# CALC3_BFSW_ICONT register map
Vendor: Texas Instruments
Peripheral module from a debugger description file (folder DRA74xP_75xP_76xP_77xP).
Registers are 32-bit, access per field, reset 0x0 unless marked. A register's access mark holds for its fields unless they carry their own. Offsets are as the file gives them; lines under a group give offsets from that group; [hi:lo] are bit positions; {n}, {i} and the like mark numbered series; 'fields as' and 'values as' point back to an identical list; <NAME> marks a mode.

## CALC3_BFSW_ICONT
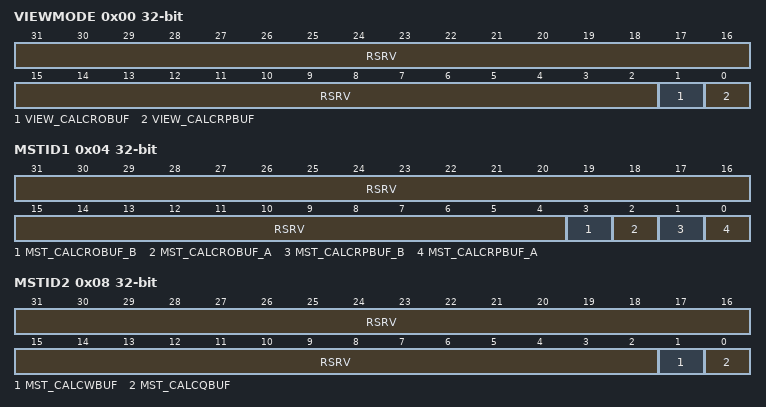
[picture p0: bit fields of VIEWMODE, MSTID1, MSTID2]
0x00 VIEWMODE — View mode register. It selects full-view mode or ping-pong view mode.
  [31:2] RSRV ro — Reserved. 0 will be returned at Read, and Write will be ignored.
  [1] VIEW_CALCROBUF rw — View mode selection for CALCROBUF. When 0, full view mode is selected. When 1, ping-pong view mode is selected.
  [0] VIEW_CALCRPBUF rw — View mode selection for CALCRPBUF. When 0, full view mode is selected. When 1, ping-pong view mode is selected.
0x04 MSTID1 — Master ID 1 Register Select master between HWA and DMA bus. This register is used in both full view and ping-pong view mode. This register is for buffers which has two physical memories. This register is affected by direct_switch_pi input port.
  [31:4] RSRV ro — Reserved. 0 will be returned at Read, and Write will be ignored.
  [3] MST_CALCROBUF_B rw — Master selection for CALCROBUF B. This bit is used in only ping-pong view mode. when 0, buffer B is assigned to DMA when 1, buffer B is assigned to HWA. This bit has no effect in full view mode. If direct_switch_pi is high, the value of this bit is inverted.
  [2] MST_CALCROBUF_A rw — Master selection for CALCROBUF A. This bit is used in both full view and ping-pong view mode. In full view mode, when 0, both buffer A and B are assigned to DMA when 1, both buffer A and B are assigned to HWA. In ping-pong view mode, when 0, buffer A is assigned to DMA when 1, buffer A is assigned to HWA. (Buffer B is not affected in ping-pong view mode.) If direct_switch_pi is high, the value of this bit is inverted.
  [1] MST_CALCRPBUF_B rw — Master selection for CALCRPBUF B. This bit is used in only ping-pong view mode. when 0, buffer B is assigned to DMA when 1, buffer B is assigned to HWA. This bit has no effect in full view mode. If direct_switch_pi is high, the value of this bit is inverted.
  [0] MST_CALCRPBUF_A rw — Master selection for CALCRPBUF A. This bit is used in both full view and ping-pong view mode. In full view mode, when 0, both buffer A and B are assigned to DMA when 1, both buffer A and B are assigned to HWA. In ping-pong view mode, when 0, buffer A is assigned to DMA when 1, buffer A is assigned to HWA. (Buffer B is not affected in ping-pong view mode.) If direct_switch_pi is high, the value of this bit is inverted.
0x08 MSTID2 — Master ID 1 Register Select master between HWA and DMA bus. This register is for buffers which has only one physical memory. This register is NOT affected by direct_switch_pi input port.
  [31:2] RSRV ro — Reserved. 0 will be returned at Read, and Write will be ignored.
  [1] MST_CALCWBUF rw — Master selection for CALCWBUF. when 0, the buffer is assigned to DMA when 1, the buffer is assigned to HWA.
  [0] MST_CALCQBUF rw — Master selection for CALCQBUF. when 0, the buffer is assigned to DMA when 1, the buffer is assigned to HWA.
